AUTOSAR XML (schema 00048)
package /ComponentTypes
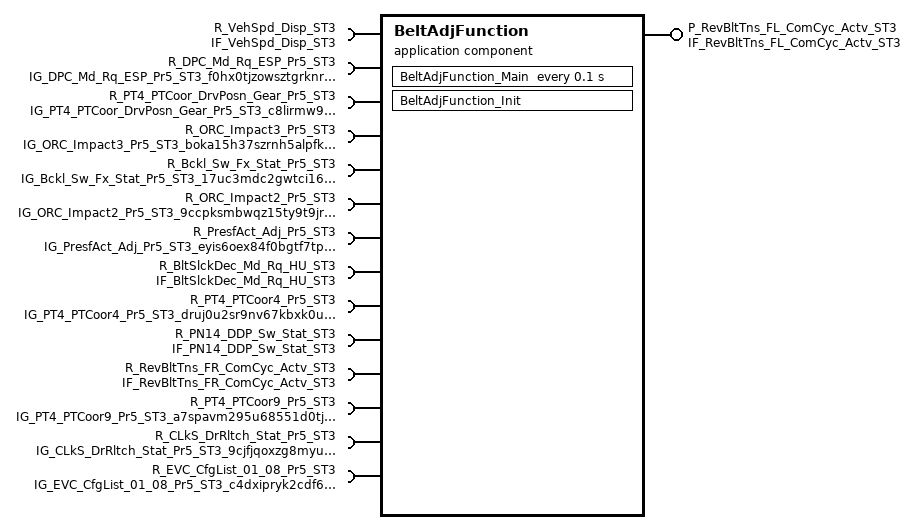
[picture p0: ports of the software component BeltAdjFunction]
  application sw component type BeltAdjFunction
    provide port P_RevBltTns_FL_ComCyc_Actv_ST3: nonqueued-sender-com-spec{data-element=RevBltTns_FL_ComCyc_Actv_ST3, init-value=constant-reference=XDIS_ays1a6ktv25pr5ggjl5ntdf5h}, provided-interface=IF_RevBltTns_FL_ComCyc_Actv_ST3  # Reversible belt tensioner front left comfort tensioning cycle active
    14 x require port:
      R_VehSpd_Disp_ST3: nonqueued-receiver-com-spec{data-element=VehSpd_Disp_ST3, alive-timeout=10.5, init-value=constant-reference=XDIS_1fl5m527mfqxrtai409n5nt6p}, required-interface=IF_VehSpd_Disp_ST3  # Displayed vehicle speed (without attenuation)
      R_DPC_Md_Rq_ESP_Pr5_ST3: nonqueued-receiver-com-spec{data-element=DPC_Md_Rq_ESP_Pr5_ST3, end-to-end-transformation-com-spec-props=disable-end-to-end-check=true, init-value=constant-reference=XDIS_2akyi0yafm6v4b7rnlmtzqky2}, required-interface=IG_DPC_Md_Rq_ESP_Pr5_ST3_f0hx0tjzowsztgrknro9jwuwh  # Dynamic select request Pr 5 ST3 (degraded)
      R_PT4_PTCoor_DrvPosn_Gear_Pr5_ST3: nonqueued-receiver-com-spec{data-element=PT4_PTCoor_DrvPosn_Gear_Pr5_ST3, end-to-end-transformation-com-spec-props=disable-end-to-end-check=true, init-value=constant-reference=XDIS_bjxptj1w89so7fpxm4dpms8ww}, required-interface=IG_PT4_PTCoor_DrvPosn_Gear_Pr5_ST3_c8lirmw9wm5odas0h648yyd4w  # PT4 PT Coor Drv position Gear Pr 5 ST3 (degraded)
      R_ORC_Impact3_Pr5_ST3: nonqueued-receiver-com-spec{data-element=ORC_Impact3_Pr5_ST3, end-to-end-transformation-com-spec-props=disable-end-to-end-check=true, init-value=constant-reference=XDIS_ayiqyrhz0dpk9ygbqo5e5w1f7}, required-interface=IG_ORC_Impact3_Pr5_ST3_boka15h37szrnh5alpfk2b7or  # ORC Impact 3 ST3 (degraded)
      R_Bckl_Sw_Fx_Stat_Pr5_ST3: nonqueued-receiver-com-spec{data-element=Bckl_Sw_Fx_Stat_Pr5_ST3, end-to-end-transformation-com-spec-props=disable-end-to-end-check=true, alive-timeout=1.1, init-value=constant-reference=XDIS_38xd6mxe7w4h211xfx307v7jd}, required-interface=IG_Bckl_Sw_Fx_Stat_Pr5_ST3_17uc3mdc2gwtci163emdxcwq  # Bckl Sw Fx state ST3 (degraded)
      R_ORC_Impact2_Pr5_ST3: nonqueued-receiver-com-spec{data-element=ORC_Impact2_Pr5_ST3, end-to-end-transformation-com-spec-props=disable-end-to-end-check=true, init-value=constant-reference=XDIS_6l5b88fcuqpu2imoz1fzls07a}, required-interface=IG_ORC_Impact2_Pr5_ST3_9ccpksmbwqz15ty9t9jr7ps1e  # ORC Impact 2 ST3 (degraded)
      R_PresfAct_Adj_Pr5_ST3: nonqueued-receiver-com-spec{data-element=PresfAct_Adj_Pr5_ST3, end-to-end-transformation-com-spec-props=disable-end-to-end-check=true, init-value=constant-reference=XDIS_klz6op2k9wci74l4e72gktkb}, required-interface=IG_PresfAct_Adj_Pr5_ST3_eyis6oex84f0bgtf7tp8d31fv  # Presf Actuator adjustment ST3 (degraded)
      R_BltSlckDec_Md_Rq_HU_ST3: nonqueued-receiver-com-spec{data-element=BltSlckDec_Md_Rq_HU_ST3, alive-timeout=60.5, init-value=constant-reference=XDIS_e0p8eo65xegbkeoit2yb8bj0v}, required-interface=IF_BltSlckDec_Md_Rq_HU_ST3  # Belt slack decreasing mode request from Head Unit
      R_PT4_PTCoor4_Pr5_ST3: nonqueued-receiver-com-spec{data-element=PT4_PTCoor4_Pr5_ST3, end-to-end-transformation-com-spec-props=disable-end-to-end-check=true, alive-timeout=1.05, init-value=constant-reference=XDIS_1j2e7ey8q28fsybvpbxfqeop8}, required-interface=IG_PT4_PTCoor4_Pr5_ST3_druj0u2sr9nv67kbxk0u6ab4e  # PT4_PTCoor4_Pr5_ST3 (degraded)
      R_PN14_DDP_Sw_Stat_ST3: nonqueued-receiver-com-spec{data-element=PN14_DDP_Sw_Stat_ST3, init-value=constant-reference=XDIS_15lbynoto8hu3um81qo7cznt0}, required-interface=IF_PN14_DDP_Sw_Stat_ST3  # Deep discharge protection switch state
      R_RevBltTns_FR_ComCyc_Actv_ST3: nonqueued-receiver-com-spec{data-element=RevBltTns_FR_ComCyc_Actv_ST3, init-value=constant-reference=XDIS_ays1a6ktv25pr5ggjl5ntdf5h}, required-interface=IF_RevBltTns_FR_ComCyc_Actv_ST3  # Reversible belt tensioner front right comfort tensioning cycle active
      R_PT4_PTCoor9_Pr5_ST3: nonqueued-receiver-com-spec{data-element=PT4_PTCoor9_Pr5_ST3, end-to-end-transformation-com-spec-props=disable-end-to-end-check=true, alive-timeout=5.1, init-value=constant-reference=XDIS_86xn4hwzmz58ui3sqboz24rhd}, required-interface=IG_PT4_PTCoor9_Pr5_ST3_a7spavm295u68551d0tj6tl4v  # PT4 PT Coor 9 Pr 5 ST3 (degraded)
      R_CLkS_DrRltch_Stat_Pr5_ST3: nonqueued-receiver-com-spec{data-element=CLkS_DrRltch_Stat_Pr5_ST3, end-to-end-transformation-com-spec-props=disable-end-to-end-check=true, init-value=constant-reference=XDIS_5tgkwvedu4465t8unm4y2yblo}, required-interface=IG_CLkS_DrRltch_Stat_Pr5_ST3_9cjfjqoxzg8myue62zdg7b3ws  # Central Locking System Rotary latch doors state (degraded)
      R_EVC_CfgList_01_08_Pr5_ST3: nonqueued-receiver-com-spec{data-element=EVC_CfgList_01_08_Pr5_ST3, end-to-end-transformation-com-spec-props=disable-end-to-end-check=true, init-value=constant-reference=XDIS_69fckmg12bk5g7417pzn53395}, required-interface=IG_EVC_CfgList_01_08_Pr5_ST3_c4dxipryk2cdf6g3u376iowg4  # EVC Cfg List 01 08 Pr 5 ST3 (degraded)
    behavior BeltAdjFunction_InternalBehavior: data-type-mapping=DataTypeMappings_DEV
      init event BeltAdjFunction_InitEvent: start-on-event=BeltAdjFunction_Init
      timing event TMT_BeltAdjFunction_Main: start-on-event=BeltAdjFunction_Main, period=0.1
      runnable BeltAdjFunction_Init
      runnable BeltAdjFunction_Main
        data-receive-point-by-arguments:
          14 x access:
            REC_R_Bckl_Sw_Fx_Stat_Pr5_ST3_Bckl_Sw_Fx_Stat_Pr5_ST3: accessed-variable=R_Bckl_Sw_Fx_Stat_Pr5_ST3.Bckl_Sw_Fx_Stat_Pr5_ST3
            REC_R_BltSlckDec_Md_Rq_HU_ST3_BltSlckDec_Md_Rq_HU_ST3: accessed-variable=R_BltSlckDec_Md_Rq_HU_ST3.BltSlckDec_Md_Rq_HU_ST3
            REC_R_CLkS_DrRltch_Stat_Pr5_ST3_CLkS_DrRltch_Stat_Pr5_ST3: accessed-variable=R_CLkS_DrRltch_Stat_Pr5_ST3.CLkS_DrRltch_Stat_Pr5_ST3
            REC_R_DPC_Md_Rq_ESP_Pr5_ST3_DPC_Md_Rq_ESP_Pr5_ST3: accessed-variable=R_DPC_Md_Rq_ESP_Pr5_ST3.DPC_Md_Rq_ESP_Pr5_ST3
            REC_R_EVC_CfgList_01_08_Pr5_ST3_EVC_CfgList_01_08_Pr5_ST3: accessed-variable=R_EVC_CfgList_01_08_Pr5_ST3.EVC_CfgList_01_08_Pr5_ST3
            REC_R_ORC_Impact2_Pr5_ST3_ORC_Impact2_Pr5_ST3: accessed-variable=R_ORC_Impact2_Pr5_ST3.ORC_Impact2_Pr5_ST3
            REC_R_ORC_Impact3_Pr5_ST3_ORC_Impact3_Pr5_ST3: accessed-variable=R_ORC_Impact3_Pr5_ST3.ORC_Impact3_Pr5_ST3
            REC_R_PN14_DDP_Sw_Stat_ST3_PN14_DDP_Sw_Stat_ST3: accessed-variable=R_PN14_DDP_Sw_Stat_ST3.PN14_DDP_Sw_Stat_ST3
            REC_R_PresfAct_Adj_Pr5_ST3_PresfAct_Adj_Pr5_ST3: accessed-variable=R_PresfAct_Adj_Pr5_ST3.PresfAct_Adj_Pr5_ST3
            REC_R_PT4_PTCoor4_Pr5_ST3_PT4_PTCoor4_Pr5_ST3: accessed-variable=R_PT4_PTCoor4_Pr5_ST3.PT4_PTCoor4_Pr5_ST3
            REC_R_PT4_PTCoor9_Pr5_ST3_PT4_PTCoor9_Pr5_ST3: accessed-variable=R_PT4_PTCoor9_Pr5_ST3.PT4_PTCoor9_Pr5_ST3
            REC_R_PT4_PTCoor_DrvPosn_Gear_Pr5_ST3_PT4_PTCoor_DrvPosn_Gear_Pr5_ST3: accessed-variable=R_PT4_PTCoor_DrvPosn_Gear_Pr5_ST3.PT4_PTCoor_DrvPosn_Gear_Pr5_ST3
            REC_R_RevBltTns_FR_ComCyc_Actv_ST3_RevBltTns_FR_ComCyc_Actv_ST3: accessed-variable=R_RevBltTns_FR_ComCyc_Actv_ST3.RevBltTns_FR_ComCyc_Actv_ST3
            REC_R_VehSpd_Disp_ST3_VehSpd_Disp_ST3: accessed-variable=R_VehSpd_Disp_ST3.VehSpd_Disp_ST3
        data-send-points:
          access SEND_P_RevBltTns_FL_ComCyc_Actv_ST3_RevBltTns_FL_ComCyc_Actv_ST3: accessed-variable=P_RevBltTns_FL_ComCyc_Actv_ST3.RevBltTns_FL_ComCyc_Actv_ST3
  swc implementation BeltAdjFunction_Implementation: behavior=BeltAdjFunction_InternalBehavior
